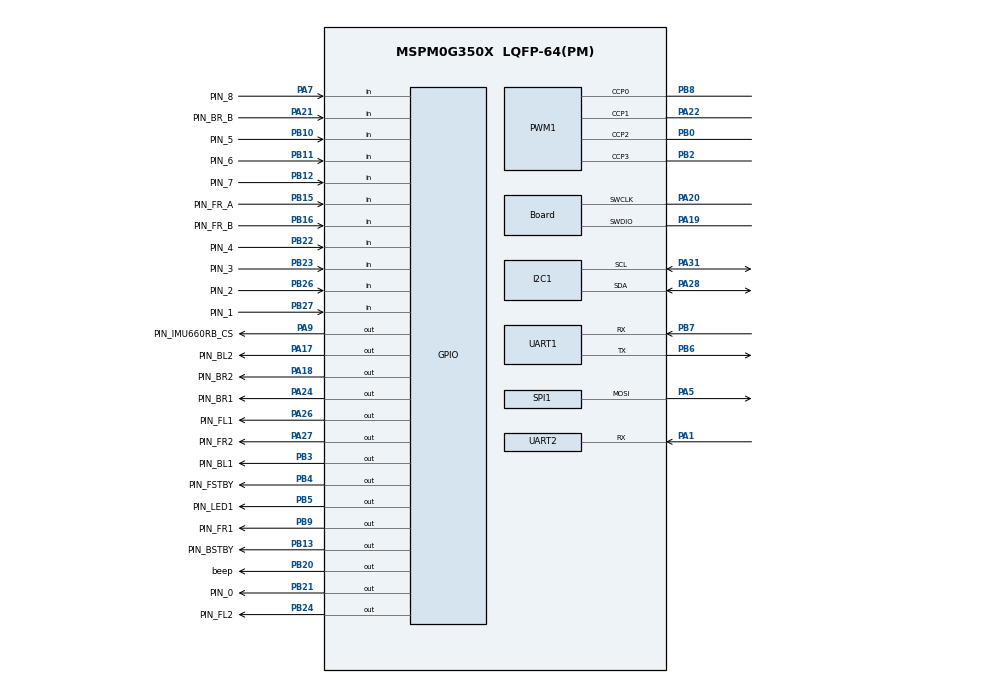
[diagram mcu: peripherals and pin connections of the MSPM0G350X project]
/**
 * @cliArgs --device "MSPM0G350X" --part "Default" --package "LQFP-64(PM)" --product "mspm0_sdk@2.05.01.00"
 * @versions {"tool":"1.23.0+4000"}
 */

/**
 * Import the modules used in this configuration.
 */
const Board         = scripting.addModule("/ti/driverlib/Board");
const GPIO          = scripting.addModule("/ti/driverlib/GPIO", {}, false);
const GPIO1         = GPIO.addInstance();
const GPIO2         = GPIO.addInstance();
const GPIO3         = GPIO.addInstance();
const GPIO4         = GPIO.addInstance();
const GPIO5         = GPIO.addInstance();
const GPIO6         = GPIO.addInstance();
const GPIO7         = GPIO.addInstance();
const I2C           = scripting.addModule("/ti/driverlib/I2C", {}, false);
const I2C1          = I2C.addInstance();
const PWM           = scripting.addModule("/ti/driverlib/PWM", {}, false);
const PWM1          = PWM.addInstance();
const SPI           = scripting.addModule("/ti/driverlib/SPI", {}, false);
const SPI1          = SPI.addInstance();
const SYSCTL        = scripting.addModule("/ti/driverlib/SYSCTL");
const TIMER         = scripting.addModule("/ti/driverlib/TIMER", {}, false);
const TIMER1        = TIMER.addInstance();
const UART          = scripting.addModule("/ti/driverlib/UART", {}, false);
const UART1         = UART.addInstance();
const UART2         = UART.addInstance();
const ProjectConfig = scripting.addModule("/ti/project_config/ProjectConfig");

/**
 * Write custom configuration values to the imported modules.
 */
Board.peripheral.swclkPin.$assign = "PA20";
Board.peripheral.swdioPin.$assign = "PA19";

GPIO1.$name                         = "GPIO_MOTOR";
GPIO1.associatedPins.create(10);
GPIO1.associatedPins[0].$name       = "PIN_FL1";
GPIO1.associatedPins[0].pin.$assign = "PA26";
GPIO1.associatedPins[1].$name       = "PIN_FL2";
GPIO1.associatedPins[1].pin.$assign = "PB24";
GPIO1.associatedPins[2].$name       = "PIN_FR1";
GPIO1.associatedPins[2].pin.$assign = "PB9";
GPIO1.associatedPins[3].$name       = "PIN_FR2";
GPIO1.associatedPins[3].pin.$assign = "PA27";
GPIO1.associatedPins[4].$name       = "PIN_BL1";
GPIO1.associatedPins[4].pin.$assign = "PB3";
GPIO1.associatedPins[5].$name       = "PIN_BL2";
GPIO1.associatedPins[5].pin.$assign = "PA17";
GPIO1.associatedPins[6].$name       = "PIN_BR1";
GPIO1.associatedPins[6].pin.$assign = "PA24";
GPIO1.associatedPins[7].$name       = "PIN_BR2";
GPIO1.associatedPins[7].pin.$assign = "PA18";
GPIO1.associatedPins[8].$name       = "PIN_FSTBY";
GPIO1.associatedPins[8].pin.$assign = "PB4";
GPIO1.associatedPins[9].$name       = "PIN_BSTBY";
GPIO1.associatedPins[9].pin.$assign = "PB13";

GPIO2.$name                              = "GPIO_LED";
GPIO2.associatedPins[0].$name            = "PIN_LED1";
GPIO2.associatedPins[0].initialValue     = "SET";
GPIO2.associatedPins[0].internalResistor = "PULL_UP";
GPIO2.associatedPins[0].pin.$assign      = "PB5";

GPIO3.$name                               = "GPIO_MOTOR_QEI";
GPIO3.associatedPins.create(8);
GPIO3.associatedPins[0].direction         = "INPUT";
GPIO3.associatedPins[0].interruptEn       = true;
GPIO3.associatedPins[0].polarity          = "RISE";
GPIO3.associatedPins[0].interruptPriority = "3";
GPIO3.associatedPins[0].$name             = "PIN_FR_A";
GPIO3.associatedPins[0].pin.$assign       = "PB15";
GPIO3.associatedPins[1].direction         = "INPUT";
GPIO3.associatedPins[1].$name             = "PIN_FR_B";
GPIO3.associatedPins[1].pin.$assign       = "PB16";
GPIO3.associatedPins[2].direction         = "INPUT";
GPIO3.associatedPins[2].interruptEn       = true;
GPIO3.associatedPins[2].polarity          = "RISE";
GPIO3.associatedPins[2].assignedPin       = "12";
GPIO3.associatedPins[2].assignedPort      = "PORTA";
GPIO3.associatedPins[2].interruptPriority = "3";
GPIO3.associatedPins[2].$name             = "PIN_FL_A";
GPIO3.associatedPins[3].direction         = "INPUT";
GPIO3.associatedPins[3].assignedPin       = "13";
GPIO3.associatedPins[3].assignedPort      = "PORTA";
GPIO3.associatedPins[3].$name             = "PIN_FL_B";
GPIO3.associatedPins[4].direction         = "INPUT";
GPIO3.associatedPins[4].interruptEn       = true;
GPIO3.associatedPins[4].polarity          = "RISE";
GPIO3.associatedPins[4].assignedPort      = "PORTB";
GPIO3.associatedPins[4].interruptPriority = "3";
GPIO3.associatedPins[4].assignedPin       = "25";
GPIO3.associatedPins[4].$name             = "PIN_BR_A";
GPIO3.associatedPins[5].direction         = "INPUT";
GPIO3.associatedPins[5].assignedPort      = "PORTA";
GPIO3.associatedPins[5].$name             = "PIN_BR_B";
GPIO3.associatedPins[5].pin.$assign       = "PA21";
GPIO3.associatedPins[6].direction         = "INPUT";
GPIO3.associatedPins[6].interruptEn       = true;
GPIO3.associatedPins[6].polarity          = "RISE";
GPIO3.associatedPins[6].assignedPort      = "PORTA";
GPIO3.associatedPins[6].assignedPin       = "25";
GPIO3.associatedPins[6].interruptPriority = "3";
GPIO3.associatedPins[6].$name             = "PIN_BL_A";
GPIO3.associatedPins[7].direction         = "INPUT";
GPIO3.associatedPins[7].assignedPort      = "PORTB";
GPIO3.associatedPins[7].assignedPin       = "17";
GPIO3.associatedPins[7].$name             = "PIN_BL_B";

GPIO4.$name                               = "GPIO_Button";
GPIO4.associatedPins[0].$name             = "PIN_0";
GPIO4.associatedPins[0].interruptEn       = true;
GPIO4.associatedPins[0].polarity          = "RISE";
GPIO4.associatedPins[0].internalResistor  = "PULL_UP";
GPIO4.associatedPins[0].launchPadShortcut = "Button3En";
GPIO4.associatedPins[0].pin.$assign       = "PB21";

GPIO5.$name                         = "GPIO_Xunji";
GPIO5.associatedPins.create(8);
GPIO5.associatedPins[0].$name       = "PIN_1";
GPIO5.associatedPins[0].direction   = "INPUT";
GPIO5.associatedPins[0].pin.$assign = "PB27";
GPIO5.associatedPins[1].$name       = "PIN_2";
GPIO5.associatedPins[1].direction   = "INPUT";
GPIO5.associatedPins[1].pin.$assign = "PB26";
GPIO5.associatedPins[2].$name       = "PIN_3";
GPIO5.associatedPins[2].direction   = "INPUT";
GPIO5.associatedPins[2].pin.$assign = "PB23";
GPIO5.associatedPins[3].$name       = "PIN_4";
GPIO5.associatedPins[3].direction   = "INPUT";
GPIO5.associatedPins[3].pin.$assign = "PB22";
GPIO5.associatedPins[4].$name       = "PIN_5";
GPIO5.associatedPins[4].direction   = "INPUT";
GPIO5.associatedPins[4].pin.$assign = "PB10";
GPIO5.associatedPins[5].$name       = "PIN_6";
GPIO5.associatedPins[5].direction   = "INPUT";
GPIO5.associatedPins[5].pin.$assign = "PB11";
GPIO5.associatedPins[6].$name       = "PIN_7";
GPIO5.associatedPins[6].direction   = "INPUT";
GPIO5.associatedPins[6].pin.$assign = "PB12";
GPIO5.associatedPins[7].$name       = "PIN_8";
GPIO5.associatedPins[7].direction   = "INPUT";
GPIO5.associatedPins[7].pin.$assign = "PA7";

GPIO6.$name                               = "GPIO_IMU660RB";
GPIO6.associatedPins.create(2);
GPIO6.associatedPins[0].$name             = "PIN_IMU660RB_CS";
GPIO6.associatedPins[0].pin.$assign       = "PA9";
GPIO6.associatedPins[1].direction         = "INPUT";
GPIO6.associatedPins[1].interruptEn       = true;
GPIO6.associatedPins[1].interruptPriority = "3";
GPIO6.associatedPins[1].polarity          = "RISE";
GPIO6.associatedPins[1].$name             = "PIN_IMU660RB_INT1";

GPIO7.$name                         = "GPIO_BEEP";
GPIO7.associatedPins[0].$name       = "beep";
GPIO7.associatedPins[0].pin.$assign = "PB20";

I2C1.$name                             = "I2C_OLED";
I2C1.basicEnableController             = true;
I2C1.basicControllerStandardBusSpeed   = "Fast";
I2C1.peripheral.sdaPin.$assign         = "PA28";
I2C1.peripheral.sclPin.$assign         = "PA31";
I2C1.sdaPinConfig.hideOutputInversion  = scripting.forceWrite(false);
I2C1.sdaPinConfig.onlyInternalResistor = scripting.forceWrite(false);
I2C1.sdaPinConfig.passedPeripheralType = scripting.forceWrite("Digital");
I2C1.sdaPinConfig.$name                = "ti_driverlib_gpio_GPIOPinGeneric6";
I2C1.sclPinConfig.hideOutputInversion  = scripting.forceWrite(false);
I2C1.sclPinConfig.onlyInternalResistor = scripting.forceWrite(false);
I2C1.sclPinConfig.passedPeripheralType = scripting.forceWrite("Digital");
I2C1.sclPinConfig.$name                = "ti_driverlib_gpio_GPIOPinGeneric8";

PWM1.$name                              = "PWM_MOTOR";
PWM1.timerCount                         = 3200;
PWM1.ccIndex                            = [0,1,2,3];
PWM1.timerStartTimer                    = true;
PWM1.PWM_CHANNEL_0.$name                = "ti_driverlib_pwm_PWMTimerCC0";
PWM1.PWM_CHANNEL_0.ccValue              = 3199;
PWM1.PWM_CHANNEL_1.$name                = "ti_driverlib_pwm_PWMTimerCC1";
PWM1.PWM_CHANNEL_1.ccValue              = 3199;
PWM1.ccp0PinConfig.direction            = scripting.forceWrite("OUTPUT");
PWM1.ccp0PinConfig.hideOutputInversion  = scripting.forceWrite(false);
PWM1.ccp0PinConfig.onlyInternalResistor = scripting.forceWrite(false);
PWM1.ccp0PinConfig.passedPeripheralType = scripting.forceWrite("Digital");
PWM1.ccp0PinConfig.$name                = "ti_driverlib_gpio_GPIOPinGeneric0";
PWM1.ccp1PinConfig.direction            = scripting.forceWrite("OUTPUT");
PWM1.ccp1PinConfig.hideOutputInversion  = scripting.forceWrite(false);
PWM1.ccp1PinConfig.onlyInternalResistor = scripting.forceWrite(false);
PWM1.ccp1PinConfig.passedPeripheralType = scripting.forceWrite("Digital");
PWM1.ccp1PinConfig.$name                = "ti_driverlib_gpio_GPIOPinGeneric1";
PWM1.peripheral.$assign                 = "TIMA0";
PWM1.peripheral.ccp0Pin.$assign         = "PB8";
PWM1.peripheral.ccp1Pin.$assign         = "PA22";
PWM1.peripheral.ccp2Pin.$assign         = "PB0";
PWM1.peripheral.ccp3Pin.$assign         = "PB2";
PWM1.PWM_CHANNEL_2.$name                = "ti_driverlib_pwm_PWMTimerCC2";
PWM1.PWM_CHANNEL_2.ccValue              = 3199;
PWM1.PWM_CHANNEL_3.$name                = "ti_driverlib_pwm_PWMTimerCC3";
PWM1.PWM_CHANNEL_3.ccValue              = 3199;
PWM1.ccp2PinConfig.$name                = "ti_driverlib_gpio_GPIOPinGeneric2";
PWM1.ccp3PinConfig.$name                = "ti_driverlib_gpio_GPIOPinGeneric3";

SPI1.$name                              = "SPI_IMU660RB";
SPI1.enableDMAEvent1                    = false;
SPI1.enableDMAEvent2                    = false;
SPI1.targetBitRate                      = 16000000;
SPI1.frameFormat                        = "MOTO3";
SPI1.sclkPinConfig.direction            = scripting.forceWrite("OUTPUT");
SPI1.sclkPinConfig.onlyInternalResistor = scripting.forceWrite(false);
SPI1.sclkPinConfig.passedPeripheralType = scripting.forceWrite("Digital");
SPI1.sclkPinConfig.$name                = "ti_driverlib_gpio_GPIOPinGeneric9";
SPI1.mosiPinConfig.direction            = scripting.forceWrite("OUTPUT");
SPI1.mosiPinConfig.hideOutputInversion  = scripting.forceWrite(false);
SPI1.mosiPinConfig.onlyInternalResistor = scripting.forceWrite(false);
SPI1.mosiPinConfig.passedPeripheralType = scripting.forceWrite("Digital");
SPI1.mosiPinConfig.$name                = "ti_driverlib_gpio_GPIOPinGeneric10";
SPI1.misoPinConfig.onlyInternalResistor = scripting.forceWrite(false);
SPI1.misoPinConfig.passedPeripheralType = scripting.forceWrite("Digital");
SPI1.misoPinConfig.$name                = "ti_driverlib_gpio_GPIOPinGeneric11";
SPI1.peripheral.mosiPin.$assign         = "PA5";

SYSCTL.forceDefaultClkConfig = true;

TIMER1.$name              = "TIMER_MS_SYS";
TIMER1.timerPeriod        = "1ms";
TIMER1.interrupts         = ["ZERO"];
TIMER1.timerMode          = "PERIODIC";
TIMER1.interruptPriority  = "1";
TIMER1.peripheral.$assign = "TIMG0";

UART1.$name                            = "UART_OPENMV";
UART1.targetBaudRate                   = 115200;
UART1.rxTimeoutValue                   = 1;
UART1.enableFIFO                       = true;
UART1.enabledInterrupts                = ["RX","RX_TIMEOUT_ERROR"];
UART1.enabledDMARXTriggers             = "DL_UART_DMA_INTERRUPT_RX";
UART1.peripheral.rxPin.$assign         = "PB7";
UART1.peripheral.txPin.$assign         = "PB6";
UART1.txPinConfig.direction            = scripting.forceWrite("OUTPUT");
UART1.txPinConfig.hideOutputInversion  = scripting.forceWrite(false);
UART1.txPinConfig.onlyInternalResistor = scripting.forceWrite(false);
UART1.txPinConfig.passedPeripheralType = scripting.forceWrite("Digital");
UART1.txPinConfig.$name                = "ti_driverlib_gpio_GPIOPinGeneric5";
UART1.rxPinConfig.hideOutputInversion  = scripting.forceWrite(false);
UART1.rxPinConfig.onlyInternalResistor = scripting.forceWrite(false);
UART1.rxPinConfig.passedPeripheralType = scripting.forceWrite("Digital");
UART1.rxPinConfig.$name                = "ti_driverlib_gpio_GPIOPinGeneric4";
UART1.DMA_CHANNEL_RX.$name             = "DMA_K230";
UART1.DMA_CHANNEL_RX.addressMode       = "f2b";
UART1.DMA_CHANNEL_RX.srcLength         = "BYTE";
UART1.DMA_CHANNEL_RX.dstLength         = "BYTE";

UART2.rxTimeoutValue                   = 1;
UART2.direction                        = "RX";
UART2.targetBaudRate                   = 115200;
UART2.enableFIFO                       = true;
UART2.$name                            = "UART_WIT";
UART2.enabledInterrupts                = ["RX_TIMEOUT_ERROR"];
UART2.enabledDMARXTriggers             = "DL_UART_DMA_INTERRUPT_RX";
UART2.rxPinConfig.hideOutputInversion  = scripting.forceWrite(false);
UART2.rxPinConfig.onlyInternalResistor = scripting.forceWrite(false);
UART2.rxPinConfig.passedPeripheralType = scripting.forceWrite("Digital");
UART2.rxPinConfig.$name                = "ti_driverlib_gpio_GPIOPinGeneric7";
UART2.peripheral.$assign               = "UART0";
UART2.peripheral.rxPin.$assign         = "PA1";
UART2.DMA_CHANNEL_RX.srcLength         = "BYTE";
UART2.DMA_CHANNEL_RX.dstLength         = "BYTE";
UART2.DMA_CHANNEL_RX.$name             = "DMA_WIT";
UART2.DMA_CHANNEL_RX.addressMode       = "f2b";

ProjectConfig.genLibIQ = true;

/**
 * Pinmux solution for unlocked pins/peripherals. This ensures that minor changes to the automatic solver in a future
 * version of the tool will not impact the pinmux you originally saw.  These lines can be completely deleted in order to
 * re-solve from scratch.
 */
Board.peripheral.$suggestSolution                = "DEBUGSS";
GPIO3.associatedPins[2].pin.$suggestSolution     = "PA12";
GPIO3.associatedPins[3].pin.$suggestSolution     = "PA13";
GPIO3.associatedPins[4].pin.$suggestSolution     = "PB25";
GPIO3.associatedPins[6].pin.$suggestSolution     = "PA25";
GPIO3.associatedPins[7].pin.$suggestSolution     = "PB17";
GPIO6.associatedPins[1].pin.$suggestSolution     = "PB14";
I2C1.peripheral.$suggestSolution                 = "I2C0";
SPI1.peripheral.$suggestSolution                 = "SPI0";
SPI1.peripheral.sclkPin.$suggestSolution         = "PA11";
SPI1.peripheral.misoPin.$suggestSolution         = "PA10";
SYSCTL.peripheral.$suggestSolution               = "SYSCTL";
UART1.peripheral.$suggestSolution                = "UART1";
UART1.DMA_CHANNEL_RX.peripheral.$suggestSolution = "DMA_CH1";
UART2.DMA_CHANNEL_RX.peripheral.$suggestSolution = "DMA_CH0";
